# CTRL_MODULE_CORE register map
Vendor: Texas Instruments
Registers are 32-bit, access per field, reset 0x0 unless marked. A register's access mark holds for its fields unless they carry their own. Offsets are as the file gives them; [hi:lo] are bit positions; 'fields as' and 'values as' point back to an identical list.

## CTRL_MODULE_CORE (part 7 of 12)
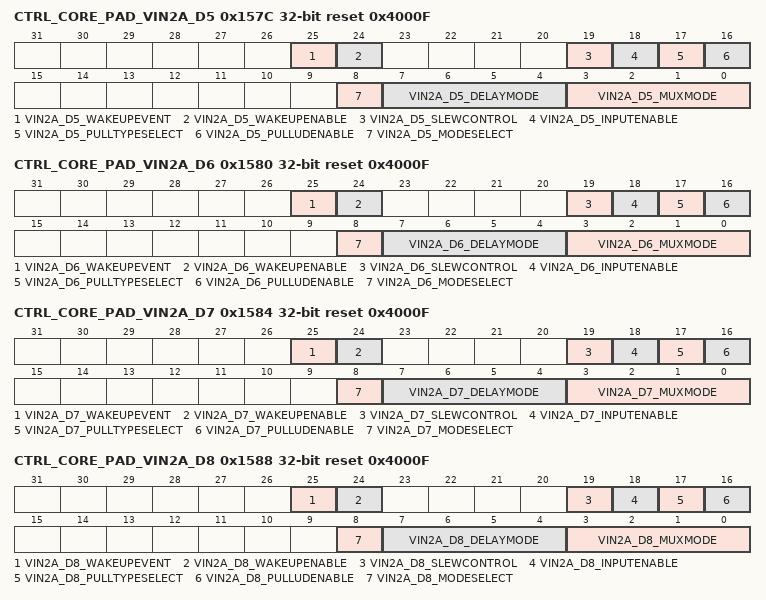
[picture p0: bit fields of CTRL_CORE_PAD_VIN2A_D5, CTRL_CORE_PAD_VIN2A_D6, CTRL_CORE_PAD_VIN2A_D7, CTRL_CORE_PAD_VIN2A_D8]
0x157C CTRL_CORE_PAD_VIN2A_D5 reset 0x4000F
  [25] VIN2A_D5_WAKEUPEVENT ro
    0=NOWAKEUP (No wakeup event detected); 1=WAKEUP (Wakeup event detected)
  [24] VIN2A_D5_WAKEUPENABLE rw
    0=DISABLE (Wakeup is disabled); 1=ENABLE (Wakeup is enabled)
  [19] VIN2A_D5_SLEWCONTROL rw
    0=FAST_SLEW (Fast slew is selected); 1=SLOW_SLEW (Slow slew is selected)
  [18] VIN2A_D5_INPUTENABLE rw
    0=DISABLE (Receive mode is disabled); 1=ENABLE (Receive mode is enabled)
  [17] VIN2A_D5_PULLTYPESELECT rw
    0=PULL_DOWN (Pull Down is selected); 1=PULL_UP (Pull Up is selected)
  [16] VIN2A_D5_PULLUDENABLE rw
    0=ENABLE (Enables weak Pull Up/Down); 1=DISABLE (Disables weak Pull Up/Down)
  [8] VIN2A_D5_MODESELECT rw — Selects between the Default IO Timing Mode and a Virtual or Manual IO Timing Mode. Refer to the device Data Manual for definition of the required settings for a given mode of operation. When this bit is 0b1, a Virtual IO Timing Mode can be selected via the DELAYMODE field of this register, as described in, Virtual IO Timing Modes. Manual IO Timing Modes are selected via the procedure described in , Manual IO Timing Modes.
    0=MUX_MODE (Default IO Timing Mode is used); 1=DELAY_MODE (A Virtual or Manual IO Timing Mode is used)
  [7:4] VIN2A_D5_DELAYMODE rw — This bit field selects the Virtual Timing Mode used when the MODESELECT bit is set to 0b1. See, Virtual IO Timing Modes for details.
  [3:0] VIN2A_D5_MUXMODE rw
    0=VIN2A_D5; 4=VOUT2_D18; 5=EMU15; 8=UART10_RTSN; 9=KBD_COL2; 10=EQEP2A_IN; 11=PR1_EDIO_SOF; 12=PR1_PRU1_GPI2; 13=PR1_PRU1_GPO2; 14=GPIO4_6; 15=DRIVER OFF
0x1580 CTRL_CORE_PAD_VIN2A_D6 reset 0x4000F
  [25] VIN2A_D6_WAKEUPEVENT ro
    values as CTRL_CORE_PAD_VIN2A_D5.VIN2A_D5_WAKEUPEVENT
  [24] VIN2A_D6_WAKEUPENABLE rw
    0=DISABLE (Wakeup is disabled); 1=ENABLE (Wakeup is enabled)
  [19] VIN2A_D6_SLEWCONTROL rw
    values as CTRL_CORE_PAD_VIN2A_D5.VIN2A_D5_SLEWCONTROL
  [18] VIN2A_D6_INPUTENABLE rw
    values as CTRL_CORE_PAD_VIN2A_D5.VIN2A_D5_INPUTENABLE
  [17] VIN2A_D6_PULLTYPESELECT rw
    values as CTRL_CORE_PAD_VIN2A_D5.VIN2A_D5_PULLTYPESELECT
  [16] VIN2A_D6_PULLUDENABLE rw
    values as CTRL_CORE_PAD_VIN2A_D5.VIN2A_D5_PULLUDENABLE
  [8] VIN2A_D6_MODESELECT rw — Selects between the Default IO Timing Mode and a Virtual or Manual IO Timing Mode. Refer to the device Data Manual for definition of the required settings for a given mode of operation. When this bit is 0b1, a Virtual IO Timing Mode can be selected via the DELAYMODE field of this register, as described in, Virtual IO Timing Modes. Manual IO Timing Modes are selected via the procedure described in , Manual IO Timing Modes.
    values as CTRL_CORE_PAD_VIN2A_D5.VIN2A_D5_MODESELECT
  [7:4] VIN2A_D6_DELAYMODE rw — This bit field selects the Virtual Timing Mode used when the MODESELECT bit is set to 0b1. See, Virtual IO Timing Modes for details.
  [3:0] VIN2A_D6_MUXMODE rw
    0=VIN2A_D6; 4=VOUT2_D17; 5=EMU16; 8=MII1_RXD1; 9=KBD_COL3; 10=EQEP2B_IN; 11=PR1_MII_MT1_CLK; 12=PR1_PRU1_GPI3; 13=PR1_PRU1_GPO3; 14=GPIO4_7; 15=DRIVER OFF
0x1584 CTRL_CORE_PAD_VIN2A_D7 reset 0x4000F
  [25] VIN2A_D7_WAKEUPEVENT ro
    values as CTRL_CORE_PAD_VIN2A_D5.VIN2A_D5_WAKEUPEVENT
  [24] VIN2A_D7_WAKEUPENABLE rw
    0=DISABLE (Wakeup is disabled); 1=ENABLE (Wakeup is enabled)
  [19] VIN2A_D7_SLEWCONTROL rw
    values as CTRL_CORE_PAD_VIN2A_D5.VIN2A_D5_SLEWCONTROL
  [18] VIN2A_D7_INPUTENABLE rw
    values as CTRL_CORE_PAD_VIN2A_D5.VIN2A_D5_INPUTENABLE
  [17] VIN2A_D7_PULLTYPESELECT rw
    values as CTRL_CORE_PAD_VIN2A_D5.VIN2A_D5_PULLTYPESELECT
  [16] VIN2A_D7_PULLUDENABLE rw
    values as CTRL_CORE_PAD_VIN2A_D5.VIN2A_D5_PULLUDENABLE
  [8] VIN2A_D7_MODESELECT rw — Selects between the Default IO Timing Mode and a Virtual or Manual IO Timing Mode. Refer to the device Data Manual for definition of the required settings for a given mode of operation. When this bit is 0b1, a Virtual IO Timing Mode can be selected via the DELAYMODE field of this register, as described in, Virtual IO Timing Modes. Manual IO Timing Modes are selected via the procedure described in , Manual IO Timing Modes.
    values as CTRL_CORE_PAD_VIN2A_D5.VIN2A_D5_MODESELECT
  [7:4] VIN2A_D7_DELAYMODE rw — This bit field selects the Virtual Timing Mode used when the MODESELECT bit is set to 0b1. See, Virtual IO Timing Modes for details.
  [3:0] VIN2A_D7_MUXMODE rw
    0=VIN2A_D7; 4=VOUT2_D16; 5=EMU17; 8=MII1_RXD2; 9=KBD_COL4; 10=EQEP2_INDEX; 11=PR1_MII1_TXEN; 12=PR1_PRU1_GPI4; 13=PR1_PRU1_GPO4; 14=GPIO4_8; 15=DRIVER OFF
0x1588 CTRL_CORE_PAD_VIN2A_D8 reset 0x4000F
  [25] VIN2A_D8_WAKEUPEVENT ro
    values as CTRL_CORE_PAD_VIN2A_D5.VIN2A_D5_WAKEUPEVENT
  [24] VIN2A_D8_WAKEUPENABLE rw
    0=DISABLE (Wakeup is disabled); 1=ENABLE (Wakeup is enabled)
  [19] VIN2A_D8_SLEWCONTROL rw
    values as CTRL_CORE_PAD_VIN2A_D5.VIN2A_D5_SLEWCONTROL
  [18] VIN2A_D8_INPUTENABLE rw
    values as CTRL_CORE_PAD_VIN2A_D5.VIN2A_D5_INPUTENABLE
  [17] VIN2A_D8_PULLTYPESELECT rw
    values as CTRL_CORE_PAD_VIN2A_D5.VIN2A_D5_PULLTYPESELECT
  [16] VIN2A_D8_PULLUDENABLE rw
    values as CTRL_CORE_PAD_VIN2A_D5.VIN2A_D5_PULLUDENABLE
  [8] VIN2A_D8_MODESELECT rw — Selects between the Default IO Timing Mode and a Virtual or Manual IO Timing Mode. Refer to the device Data Manual for definition of the required settings for a given mode of operation. When this bit is 0b1, a Virtual IO Timing Mode can be selected via the DELAYMODE field of this register, as described in, Virtual IO Timing Modes. Manual IO Timing Modes are selected via the procedure described in , Manual IO Timing Modes.
    values as CTRL_CORE_PAD_VIN2A_D5.VIN2A_D5_MODESELECT
  [7:4] VIN2A_D8_DELAYMODE rw — This bit field selects the Virtual Timing Mode used when the MODESELECT bit is set to 0b1. See, Virtual IO Timing Modes for details.
  [3:0] VIN2A_D8_MUXMODE rw
    0=VIN2A_D8; 4=VOUT2_D15; 5=EMU18; 8=MII1_RXD3; 9=KBD_COL5; 10=EQEP2_STROBE; 11=PR1_MII1_TXD3; 12=PR1_PRU1_GPI5; 13=PR1_PRU1_GPO5; 14=GPIO4_9; 15=DRIVER OFF
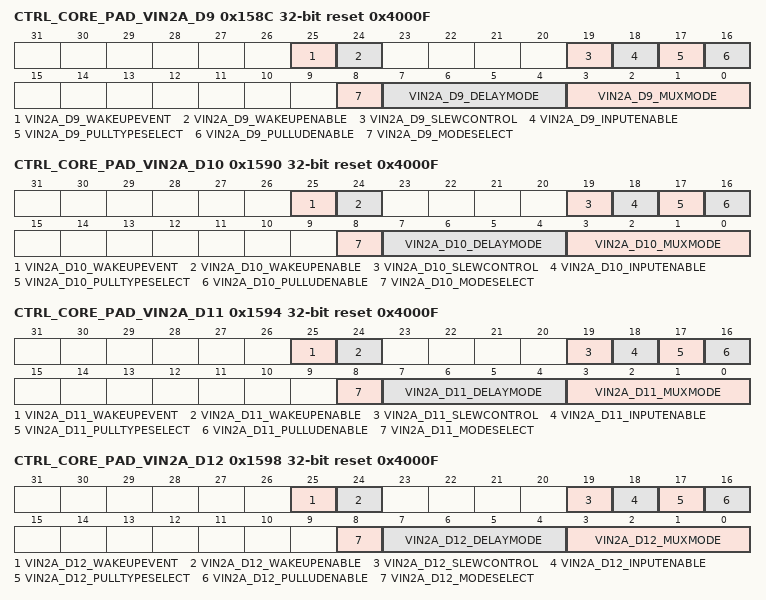
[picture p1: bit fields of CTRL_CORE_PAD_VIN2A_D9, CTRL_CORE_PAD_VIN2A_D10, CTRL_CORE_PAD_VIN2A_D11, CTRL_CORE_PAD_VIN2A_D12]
0x158C CTRL_CORE_PAD_VIN2A_D9 reset 0x4000F
  [25] VIN2A_D9_WAKEUPEVENT ro
    values as CTRL_CORE_PAD_VIN2A_D5.VIN2A_D5_WAKEUPEVENT
  [24] VIN2A_D9_WAKEUPENABLE rw
    0=DISABLE (Wakeup is disabled); 1=ENABLE (Wakeup is enabled)
  [19] VIN2A_D9_SLEWCONTROL rw
    values as CTRL_CORE_PAD_VIN2A_D5.VIN2A_D5_SLEWCONTROL
  [18] VIN2A_D9_INPUTENABLE rw
    values as CTRL_CORE_PAD_VIN2A_D5.VIN2A_D5_INPUTENABLE
  [17] VIN2A_D9_PULLTYPESELECT rw
    values as CTRL_CORE_PAD_VIN2A_D5.VIN2A_D5_PULLTYPESELECT
  [16] VIN2A_D9_PULLUDENABLE rw
    values as CTRL_CORE_PAD_VIN2A_D5.VIN2A_D5_PULLUDENABLE
  [8] VIN2A_D9_MODESELECT rw — Selects between the Default IO Timing Mode and a Virtual or Manual IO Timing Mode. Refer to the device Data Manual for definition of the required settings for a given mode of operation. When this bit is 0b1, a Virtual IO Timing Mode can be selected via the DELAYMODE field of this register, as described in, Virtual IO Timing Modes. Manual IO Timing Modes are selected via the procedure described in , Manual IO Timing Modes.
    values as CTRL_CORE_PAD_VIN2A_D5.VIN2A_D5_MODESELECT
  [7:4] VIN2A_D9_DELAYMODE rw — This bit field selects the Virtual Timing Mode used when the MODESELECT bit is set to 0b1. See, Virtual IO Timing Modes for details.
  [3:0] VIN2A_D9_MUXMODE rw
    0=VIN2A_D9; 4=VOUT2_D14; 5=EMU19; 8=MII1_RXD0; 9=KBD_COL6; 10=EHRPWM2A; 11=PR1_MII1_TXD2; 12=PR1_PRU1_GPI6; 13=PR1_PRU1_GPO6; 14=GPIO4_10; 15=DRIVER OFF
0x1590 CTRL_CORE_PAD_VIN2A_D10 reset 0x4000F
  [25] VIN2A_D10_WAKEUPEVENT ro
    values as CTRL_CORE_PAD_VIN2A_D5.VIN2A_D5_WAKEUPEVENT
  [24] VIN2A_D10_WAKEUPENABLE rw
    0=DISABLE (Wakeup is disabled); 1=ENABLE (Wakeup is enabled)
  [19] VIN2A_D10_SLEWCONTROL rw
    values as CTRL_CORE_PAD_VIN2A_D5.VIN2A_D5_SLEWCONTROL
  [18] VIN2A_D10_INPUTENABLE rw
    values as CTRL_CORE_PAD_VIN2A_D5.VIN2A_D5_INPUTENABLE
  [17] VIN2A_D10_PULLTYPESELECT rw
    values as CTRL_CORE_PAD_VIN2A_D5.VIN2A_D5_PULLTYPESELECT
  [16] VIN2A_D10_PULLUDENABLE rw
    values as CTRL_CORE_PAD_VIN2A_D5.VIN2A_D5_PULLUDENABLE
  [8] VIN2A_D10_MODESELECT rw — Selects between the Default IO Timing Mode and a Virtual or Manual IO Timing Mode. Refer to the device Data Manual for definition of the required settings for a given mode of operation. When this bit is 0b1, a Virtual IO Timing Mode can be selected via the DELAYMODE field of this register, as described in, Virtual IO Timing Modes. Manual IO Timing Modes are selected via the procedure described in , Manual IO Timing Modes.
    values as CTRL_CORE_PAD_VIN2A_D5.VIN2A_D5_MODESELECT
  [7:4] VIN2A_D10_DELAYMODE rw — This bit field selects the Virtual Timing Mode used when the MODESELECT bit is set to 0b1. See, Virtual IO Timing Modes for details.
  [3:0] VIN2A_D10_MUXMODE rw
    0=VIN2A_D10; 3=MDIO_MCLK; 4=VOUT2_D13; 9=KBD_COL7; 10=EHRPWM2B; 11=PR1_MDIO_MDCLK; 12=PR1_PRU1_GPI7; 13=PR1_PRU1_GPO7; 14=GPIO4_11; 15=DRIVER OFF
0x1594 CTRL_CORE_PAD_VIN2A_D11 reset 0x4000F
  [25] VIN2A_D11_WAKEUPEVENT ro
    values as CTRL_CORE_PAD_VIN2A_D5.VIN2A_D5_WAKEUPEVENT
  [24] VIN2A_D11_WAKEUPENABLE rw
    0=DISABLE (Wakeup is disabled); 1=ENABLE (Wakeup is enabled)
  [19] VIN2A_D11_SLEWCONTROL rw
    values as CTRL_CORE_PAD_VIN2A_D5.VIN2A_D5_SLEWCONTROL
  [18] VIN2A_D11_INPUTENABLE rw
    values as CTRL_CORE_PAD_VIN2A_D5.VIN2A_D5_INPUTENABLE
  [17] VIN2A_D11_PULLTYPESELECT rw
    values as CTRL_CORE_PAD_VIN2A_D5.VIN2A_D5_PULLTYPESELECT
  [16] VIN2A_D11_PULLUDENABLE rw
    values as CTRL_CORE_PAD_VIN2A_D5.VIN2A_D5_PULLUDENABLE
  [8] VIN2A_D11_MODESELECT rw — Selects between the Default IO Timing Mode and a Virtual or Manual IO Timing Mode. Refer to the device Data Manual for definition of the required settings for a given mode of operation. When this bit is 0b1, a Virtual IO Timing Mode can be selected via the DELAYMODE field of this register, as described in, Virtual IO Timing Modes. Manual IO Timing Modes are selected via the procedure described in , Manual IO Timing Modes.
    values as CTRL_CORE_PAD_VIN2A_D5.VIN2A_D5_MODESELECT
  [7:4] VIN2A_D11_DELAYMODE rw — This bit field selects the Virtual Timing Mode used when the MODESELECT bit is set to 0b1. See, Virtual IO Timing Modes for details.
  [3:0] VIN2A_D11_MUXMODE rw
    0=VIN2A_D11; 3=MDIO_D; 4=VOUT2_D12; 9=KBD_ROW7; 10=EHRPWM2_TRIPZONE_INPUT; 11=PR1_MDIO_DATA; 12=PR1_PRU1_GPI8; 13=PR1_PRU1_GPO8; 14=GPIO4_12; 15=DRIVER OFF
0x1598 CTRL_CORE_PAD_VIN2A_D12 reset 0x4000F
  [25] VIN2A_D12_WAKEUPEVENT ro
    values as CTRL_CORE_PAD_VIN2A_D5.VIN2A_D5_WAKEUPEVENT
  [24] VIN2A_D12_WAKEUPENABLE rw
    0=DISABLE (Wakeup is disabled); 1=ENABLE (Wakeup is enabled)
  [19] VIN2A_D12_SLEWCONTROL rw
    values as CTRL_CORE_PAD_VIN2A_D5.VIN2A_D5_SLEWCONTROL
  [18] VIN2A_D12_INPUTENABLE rw
    values as CTRL_CORE_PAD_VIN2A_D5.VIN2A_D5_INPUTENABLE
  [17] VIN2A_D12_PULLTYPESELECT rw
    values as CTRL_CORE_PAD_VIN2A_D5.VIN2A_D5_PULLTYPESELECT
  [16] VIN2A_D12_PULLUDENABLE rw
    values as CTRL_CORE_PAD_VIN2A_D5.VIN2A_D5_PULLUDENABLE
  [8] VIN2A_D12_MODESELECT rw — Selects between the Default IO Timing Mode and a Virtual or Manual IO Timing Mode. Refer to the device Data Manual for definition of the required settings for a given mode of operation. When this bit is 0b1, a Virtual IO Timing Mode can be selected via the DELAYMODE field of this register, as described in, Virtual IO Timing Modes. Manual IO Timing Modes are selected via the procedure described in , Manual IO Timing Modes.
    values as CTRL_CORE_PAD_VIN2A_D5.VIN2A_D5_MODESELECT
  [7:4] VIN2A_D12_DELAYMODE rw — This bit field selects the Virtual Timing Mode used when the MODESELECT bit is set to 0b1. See, Virtual IO Timing Modes for details.
  [3:0] VIN2A_D12_MUXMODE rw
    0=VIN2A_D12; 3=RGMII1_TXC; 4=VOUT2_D11; 8=MII1_RXCLK; 9=KBD_COL8; 10=ECAP2_IN_PWM2_OUT; 11=PR1_MII1_TXD1; 12=PR1_PRU1_GPI9; 13=PR1_PRU1_GPO9; 14=GPIO4_13; 15=DRIVER OFF
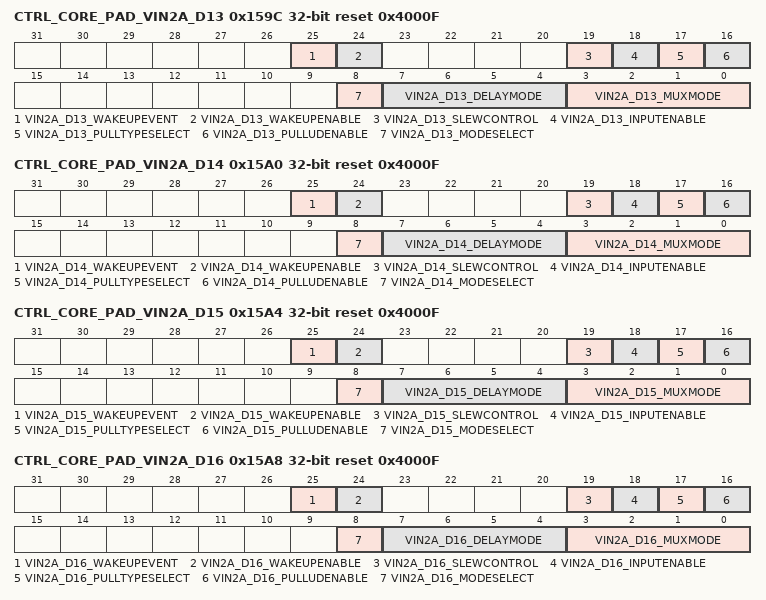
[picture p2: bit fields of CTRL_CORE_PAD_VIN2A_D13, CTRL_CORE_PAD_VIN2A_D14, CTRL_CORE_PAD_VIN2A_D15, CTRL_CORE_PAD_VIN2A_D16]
0x159C CTRL_CORE_PAD_VIN2A_D13 reset 0x4000F
  [25] VIN2A_D13_WAKEUPEVENT ro
    values as CTRL_CORE_PAD_VIN2A_D5.VIN2A_D5_WAKEUPEVENT
  [24] VIN2A_D13_WAKEUPENABLE rw
    0=DISABLE (Wakeup is disabled); 1=ENABLE (Wakeup is enabled)
  [19] VIN2A_D13_SLEWCONTROL rw
    values as CTRL_CORE_PAD_VIN2A_D5.VIN2A_D5_SLEWCONTROL
  [18] VIN2A_D13_INPUTENABLE rw
    values as CTRL_CORE_PAD_VIN2A_D5.VIN2A_D5_INPUTENABLE
  [17] VIN2A_D13_PULLTYPESELECT rw
    values as CTRL_CORE_PAD_VIN2A_D5.VIN2A_D5_PULLTYPESELECT
  [16] VIN2A_D13_PULLUDENABLE rw
    values as CTRL_CORE_PAD_VIN2A_D5.VIN2A_D5_PULLUDENABLE
  [8] VIN2A_D13_MODESELECT rw — Selects between the Default IO Timing Mode and a Virtual or Manual IO Timing Mode. Refer to the device Data Manual for definition of the required settings for a given mode of operation. When this bit is 0b1, a Virtual IO Timing Mode can be selected via the DELAYMODE field of this register, as described in, Virtual IO Timing Modes. Manual IO Timing Modes are selected via the procedure described in , Manual IO Timing Modes.
    values as CTRL_CORE_PAD_VIN2A_D5.VIN2A_D5_MODESELECT
  [7:4] VIN2A_D13_DELAYMODE rw — This bit field selects the Virtual Timing Mode used when the MODESELECT bit is set to 0b1. See, Virtual IO Timing Modes for details.
  [3:0] VIN2A_D13_MUXMODE rw
    0=VIN2A_D13; 3=RGMII1_TXCTL; 4=VOUT2_D10; 8=MII1_RXDV; 9=KBD_ROW8; 10=EQEP3A_IN; 11=PR1_MII1_TXD0; 12=PR1_PRU1_GPI10; 13=PR1_PRU1_GPO10; 14=GPIO4_14; 15=DRIVER OFF
0x15A0 CTRL_CORE_PAD_VIN2A_D14 reset 0x4000F
  [25] VIN2A_D14_WAKEUPEVENT ro
    values as CTRL_CORE_PAD_VIN2A_D5.VIN2A_D5_WAKEUPEVENT
  [24] VIN2A_D14_WAKEUPENABLE rw
    0=DISABLE (Wakeup is disabled); 1=ENABLE (Wakeup is enabled)
  [19] VIN2A_D14_SLEWCONTROL rw
    values as CTRL_CORE_PAD_VIN2A_D5.VIN2A_D5_SLEWCONTROL
  [18] VIN2A_D14_INPUTENABLE rw
    values as CTRL_CORE_PAD_VIN2A_D5.VIN2A_D5_INPUTENABLE
  [17] VIN2A_D14_PULLTYPESELECT rw
    values as CTRL_CORE_PAD_VIN2A_D5.VIN2A_D5_PULLTYPESELECT
  [16] VIN2A_D14_PULLUDENABLE rw
    values as CTRL_CORE_PAD_VIN2A_D5.VIN2A_D5_PULLUDENABLE
  [8] VIN2A_D14_MODESELECT rw — Selects between the Default IO Timing Mode and a Virtual or Manual IO Timing Mode. Refer to the device Data Manual for definition of the required settings for a given mode of operation. When this bit is 0b1, a Virtual IO Timing Mode can be selected via the DELAYMODE field of this register, as described in, Virtual IO Timing Modes. Manual IO Timing Modes are selected via the procedure described in , Manual IO Timing Modes.
    values as CTRL_CORE_PAD_VIN2A_D5.VIN2A_D5_MODESELECT
  [7:4] VIN2A_D14_DELAYMODE rw — This bit field selects the Virtual Timing Mode used when the MODESELECT bit is set to 0b1. See, Virtual IO Timing Modes for details.
  [3:0] VIN2A_D14_MUXMODE rw
    0=VIN2A_D14; 3=RGMII1_TXD3; 4=VOUT2_D9; 8=MII1_TXCLK; 10=EQEP3B_IN; 11=PR1_MII_MR1_CLK; 12=PR1_PRU1_GPI11; 13=PR1_PRU1_GPO11; 14=GPIO4_15; 15=DRIVER OFF
0x15A4 CTRL_CORE_PAD_VIN2A_D15 reset 0x4000F
  [25] VIN2A_D15_WAKEUPEVENT ro
    values as CTRL_CORE_PAD_VIN2A_D5.VIN2A_D5_WAKEUPEVENT
  [24] VIN2A_D15_WAKEUPENABLE rw
    0=DISABLE (Wakeup is disabled); 1=ENABLE (Wakeup is enabled)
  [19] VIN2A_D15_SLEWCONTROL rw
    values as CTRL_CORE_PAD_VIN2A_D5.VIN2A_D5_SLEWCONTROL
  [18] VIN2A_D15_INPUTENABLE rw
    values as CTRL_CORE_PAD_VIN2A_D5.VIN2A_D5_INPUTENABLE
  [17] VIN2A_D15_PULLTYPESELECT rw
    values as CTRL_CORE_PAD_VIN2A_D5.VIN2A_D5_PULLTYPESELECT
  [16] VIN2A_D15_PULLUDENABLE rw
    values as CTRL_CORE_PAD_VIN2A_D5.VIN2A_D5_PULLUDENABLE
  [8] VIN2A_D15_MODESELECT rw — Selects between the Default IO Timing Mode and a Virtual or Manual IO Timing Mode. Refer to the device Data Manual for definition of the required settings for a given mode of operation. When this bit is 0b1, a Virtual IO Timing Mode can be selected via the DELAYMODE field of this register, as described in, Virtual IO Timing Modes. Manual IO Timing Modes are selected via the procedure described in , Manual IO Timing Modes.
    values as CTRL_CORE_PAD_VIN2A_D5.VIN2A_D5_MODESELECT
  [7:4] VIN2A_D15_DELAYMODE rw — This bit field selects the Virtual Timing Mode used when the MODESELECT bit is set to 0b1. See, Virtual IO Timing Modes for details.
  [3:0] VIN2A_D15_MUXMODE rw
    0=VIN2A_D15; 3=RGMII1_TXD2; 4=VOUT2_D8; 8=MII1_TXD0; 10=EQEP3_INDEX; 11=PR1_MII1_RXDV; 12=PR1_PRU1_GPI12; 13=PR1_PRU1_GPO12; 14=GPIO4_16; 15=DRIVER OFF
0x15A8 CTRL_CORE_PAD_VIN2A_D16 reset 0x4000F
  [25] VIN2A_D16_WAKEUPEVENT ro
    values as CTRL_CORE_PAD_VIN2A_D5.VIN2A_D5_WAKEUPEVENT
  [24] VIN2A_D16_WAKEUPENABLE rw
    0=DISABLE (Wakeup is disabled); 1=ENABLE (Wakeup is enabled)
  [19] VIN2A_D16_SLEWCONTROL rw
    values as CTRL_CORE_PAD_VIN2A_D5.VIN2A_D5_SLEWCONTROL
  [18] VIN2A_D16_INPUTENABLE rw
    values as CTRL_CORE_PAD_VIN2A_D5.VIN2A_D5_INPUTENABLE
  [17] VIN2A_D16_PULLTYPESELECT rw
    values as CTRL_CORE_PAD_VIN2A_D5.VIN2A_D5_PULLTYPESELECT
  [16] VIN2A_D16_PULLUDENABLE rw
    values as CTRL_CORE_PAD_VIN2A_D5.VIN2A_D5_PULLUDENABLE
  [8] VIN2A_D16_MODESELECT rw — Selects between the Default IO Timing Mode and a Virtual or Manual IO Timing Mode. Refer to the device Data Manual for definition of the required settings for a given mode of operation. When this bit is 0b1, a Virtual IO Timing Mode can be selected via the DELAYMODE field of this register, as described in, Virtual IO Timing Modes. Manual IO Timing Modes are selected via the procedure described in , Manual IO Timing Modes.
    values as CTRL_CORE_PAD_VIN2A_D5.VIN2A_D5_MODESELECT
  [7:4] VIN2A_D16_DELAYMODE rw — This bit field selects the Virtual Timing Mode used when the MODESELECT bit is set to 0b1. See, Virtual IO Timing Modes for details.
  [3:0] VIN2A_D16_MUXMODE rw
    0=VIN2A_D16; 2=VIN2B_D7; 3=RGMII1_TXD1; 4=VOUT2_D7; 6=VIN3A_D8; 8=MII1_TXD1; 10=EQEP3_STROBE; 11=PR1_MII1_RXD3; 12=PR1_PRU1_GPI13; 13=PR1_PRU1_GPO13; 14=GPIO4_24; 15=DRIVER OFF
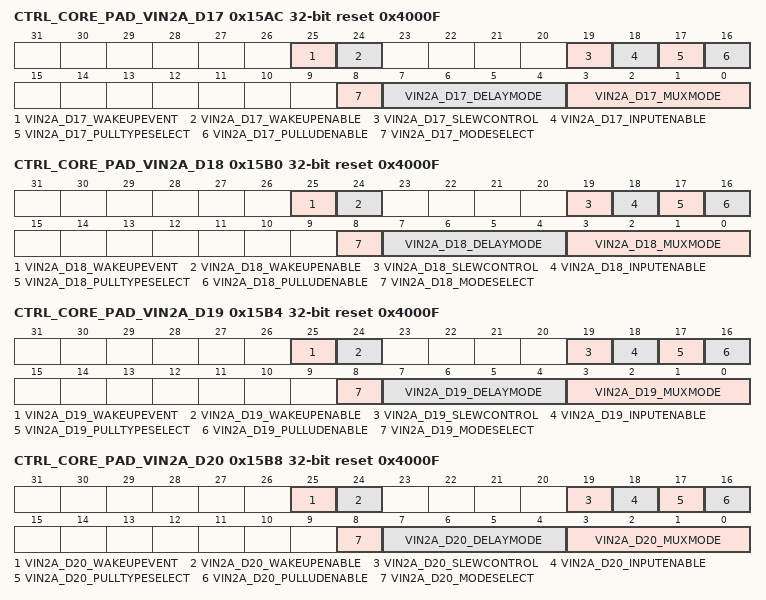
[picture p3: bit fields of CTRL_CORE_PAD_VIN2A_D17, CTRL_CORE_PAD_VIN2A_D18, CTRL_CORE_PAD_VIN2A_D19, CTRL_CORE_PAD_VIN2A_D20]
0x15AC CTRL_CORE_PAD_VIN2A_D17 reset 0x4000F
  [25] VIN2A_D17_WAKEUPEVENT ro
    values as CTRL_CORE_PAD_VIN2A_D5.VIN2A_D5_WAKEUPEVENT
  [24] VIN2A_D17_WAKEUPENABLE rw
    0=DISABLE (Wakeup is disabled); 1=ENABLE (Wakeup is enabled)
  [19] VIN2A_D17_SLEWCONTROL rw
    values as CTRL_CORE_PAD_VIN2A_D5.VIN2A_D5_SLEWCONTROL
  [18] VIN2A_D17_INPUTENABLE rw
    values as CTRL_CORE_PAD_VIN2A_D5.VIN2A_D5_INPUTENABLE
  [17] VIN2A_D17_PULLTYPESELECT rw
    values as CTRL_CORE_PAD_VIN2A_D5.VIN2A_D5_PULLTYPESELECT
  [16] VIN2A_D17_PULLUDENABLE rw
    values as CTRL_CORE_PAD_VIN2A_D5.VIN2A_D5_PULLUDENABLE
  [8] VIN2A_D17_MODESELECT rw — Selects between the Default IO Timing Mode and a Virtual or Manual IO Timing Mode. Refer to the device Data Manual for definition of the required settings for a given mode of operation. When this bit is 0b1, a Virtual IO Timing Mode can be selected via the DELAYMODE field of this register, as described in, Virtual IO Timing Modes. Manual IO Timing Modes are selected via the procedure described in , Manual IO Timing Modes.
    values as CTRL_CORE_PAD_VIN2A_D5.VIN2A_D5_MODESELECT
  [7:4] VIN2A_D17_DELAYMODE rw — This bit field selects the Virtual Timing Mode used when the MODESELECT bit is set to 0b1. See, Virtual IO Timing Modes for details.
  [3:0] VIN2A_D17_MUXMODE rw
    0=VIN2A_D17; 2=VIN2B_D6; 3=RGMII1_TXD0; 4=VOUT2_D6; 6=VIN3A_D9; 8=MII1_TXD2; 10=EHRPWM3A; 11=PR1_MII1_RXD2; 12=PR1_PRU1_GPI14; 13=PR1_PRU1_GPO14; 14=GPIO4_25; 15=DRIVER OFF
0x15B0 CTRL_CORE_PAD_VIN2A_D18 reset 0x4000F
  [25] VIN2A_D18_WAKEUPEVENT ro
    values as CTRL_CORE_PAD_VIN2A_D5.VIN2A_D5_WAKEUPEVENT
  [24] VIN2A_D18_WAKEUPENABLE rw
    0=DISABLE (Wakeup is disabled); 1=ENABLE (Wakeup is enabled)
  [19] VIN2A_D18_SLEWCONTROL rw
    values as CTRL_CORE_PAD_VIN2A_D5.VIN2A_D5_SLEWCONTROL
  [18] VIN2A_D18_INPUTENABLE rw
    values as CTRL_CORE_PAD_VIN2A_D5.VIN2A_D5_INPUTENABLE
  [17] VIN2A_D18_PULLTYPESELECT rw
    values as CTRL_CORE_PAD_VIN2A_D5.VIN2A_D5_PULLTYPESELECT
  [16] VIN2A_D18_PULLUDENABLE rw
    values as CTRL_CORE_PAD_VIN2A_D5.VIN2A_D5_PULLUDENABLE
  [8] VIN2A_D18_MODESELECT rw — Selects between the Default IO Timing Mode and a Virtual or Manual IO Timing Mode. Refer to the device Data Manual for definition of the required settings for a given mode of operation. When this bit is 0b1, a Virtual IO Timing Mode can be selected via the DELAYMODE field of this register, as described in, Virtual IO Timing Modes. Manual IO Timing Modes are selected via the procedure described in , Manual IO Timing Modes.
    values as CTRL_CORE_PAD_VIN2A_D5.VIN2A_D5_MODESELECT
  [7:4] VIN2A_D18_DELAYMODE rw — This bit field selects the Virtual Timing Mode used when the MODESELECT bit is set to 0b1. See, Virtual IO Timing Modes for details.
  [3:0] VIN2A_D18_MUXMODE rw
    0=VIN2A_D18; 2=VIN2B_D5; 3=RGMII1_RXC; 4=VOUT2_D5; 6=VIN3A_D10; 8=MII1_TXD3; 10=EHRPWM3B; 11=PR1_MII1_RXD1; 12=PR1_PRU1_GPI15; 13=PR1_PRU1_GPO15; 14=GPIO4_26; 15=DRIVER OFF
0x15B4 CTRL_CORE_PAD_VIN2A_D19 reset 0x4000F
  [25] VIN2A_D19_WAKEUPEVENT ro
    values as CTRL_CORE_PAD_VIN2A_D5.VIN2A_D5_WAKEUPEVENT
  [24] VIN2A_D19_WAKEUPENABLE rw
    0=DISABLE (Wakeup is disabled); 1=ENABLE (Wakeup is enabled)
  [19] VIN2A_D19_SLEWCONTROL rw
    values as CTRL_CORE_PAD_VIN2A_D5.VIN2A_D5_SLEWCONTROL
  [18] VIN2A_D19_INPUTENABLE rw
    values as CTRL_CORE_PAD_VIN2A_D5.VIN2A_D5_INPUTENABLE
  [17] VIN2A_D19_PULLTYPESELECT rw
    values as CTRL_CORE_PAD_VIN2A_D5.VIN2A_D5_PULLTYPESELECT
  [16] VIN2A_D19_PULLUDENABLE rw
    values as CTRL_CORE_PAD_VIN2A_D5.VIN2A_D5_PULLUDENABLE
  [8] VIN2A_D19_MODESELECT rw — Selects between the Default IO Timing Mode and a Virtual or Manual IO Timing Mode. Refer to the device Data Manual for definition of the required settings for a given mode of operation. When this bit is 0b1, a Virtual IO Timing Mode can be selected via the DELAYMODE field of this register, as described in, Virtual IO Timing Modes. Manual IO Timing Modes are selected via the procedure described in , Manual IO Timing Modes.
    values as CTRL_CORE_PAD_VIN2A_D5.VIN2A_D5_MODESELECT
  [7:4] VIN2A_D19_DELAYMODE rw — This bit field selects the Virtual Timing Mode used when the MODESELECT bit is set to 0b1. See, Virtual IO Timing Modes for details.
  [3:0] VIN2A_D19_MUXMODE rw
    0=VIN2A_D19; 2=VIN2B_D4; 3=RGMII1_RXCTL; 4=VOUT2_D4; 6=VIN3A_D11; 8=MII1_TXER; 10=EHRPWM3_TRIPZONE_INPUT; 11=PR1_MII1_RXD0; 12=PR1_PRU1_GPI16; 13=PR1_PRU1_GPO16; 14=GPIO4_27; 15=DRIVER OFF
0x15B8 CTRL_CORE_PAD_VIN2A_D20 reset 0x4000F
  [25] VIN2A_D20_WAKEUPEVENT ro
    values as CTRL_CORE_PAD_VIN2A_D5.VIN2A_D5_WAKEUPEVENT
  [24] VIN2A_D20_WAKEUPENABLE rw
    0=DISABLE (Wakeup is disabled); 1=ENABLE (Wakeup is enabled)
  [19] VIN2A_D20_SLEWCONTROL rw
    values as CTRL_CORE_PAD_VIN2A_D5.VIN2A_D5_SLEWCONTROL
  [18] VIN2A_D20_INPUTENABLE rw
    values as CTRL_CORE_PAD_VIN2A_D5.VIN2A_D5_INPUTENABLE
  [17] VIN2A_D20_PULLTYPESELECT rw
    values as CTRL_CORE_PAD_VIN2A_D5.VIN2A_D5_PULLTYPESELECT
  [16] VIN2A_D20_PULLUDENABLE rw
    values as CTRL_CORE_PAD_VIN2A_D5.VIN2A_D5_PULLUDENABLE
  [8] VIN2A_D20_MODESELECT rw — Selects between the Default IO Timing Mode and a Virtual or Manual IO Timing Mode. Refer to the device Data Manual for definition of the required settings for a given mode of operation. When this bit is 0b1, a Virtual IO Timing Mode can be selected via the DELAYMODE field of this register, as described in, Virtual IO Timing Modes. Manual IO Timing Modes are selected via the procedure described in , Manual IO Timing Modes.
    values as CTRL_CORE_PAD_VIN2A_D5.VIN2A_D5_MODESELECT
  [7:4] VIN2A_D20_DELAYMODE rw — This bit field selects the Virtual Timing Mode used when the MODESELECT bit is set to 0b1. See, Virtual IO Timing Modes for details.
  [3:0] VIN2A_D20_MUXMODE rw
    0=VIN2A_D20; 2=VIN2B_D3; 3=RGMII1_RXD3; 4=VOUT2_D3; 5=VIN3A_DE0; 6=VIN3A_D12; 8=MII1_RXER; 10=ECAP3_IN_PWM3_OUT; 11=PR1_MII1_RXER; 12=PR1_PRU1_GPI17; 13=PR1_PRU1_GPO17; 14=GPIO4_28; 15=DRIVER OFF
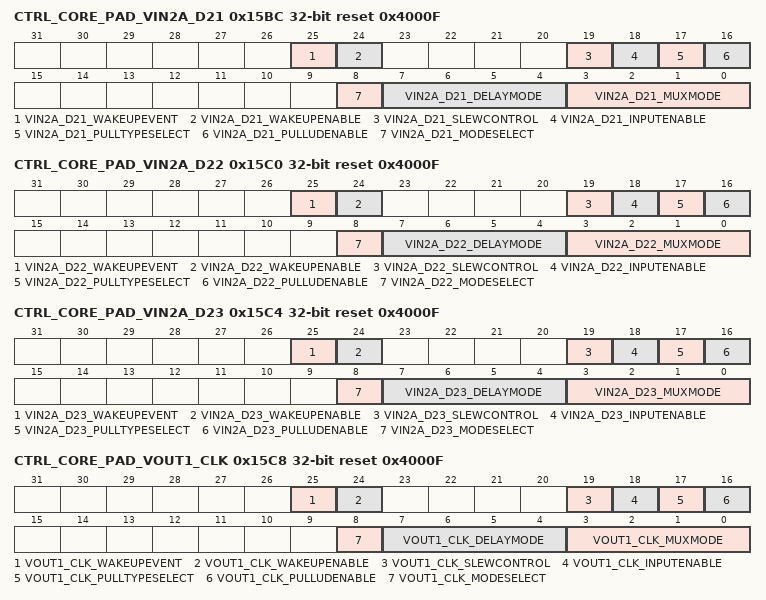
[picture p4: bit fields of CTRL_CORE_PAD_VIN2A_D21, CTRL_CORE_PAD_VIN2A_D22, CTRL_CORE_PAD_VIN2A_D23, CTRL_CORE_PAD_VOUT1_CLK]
0x15BC CTRL_CORE_PAD_VIN2A_D21 reset 0x4000F
  [25] VIN2A_D21_WAKEUPEVENT ro
    values as CTRL_CORE_PAD_VIN2A_D5.VIN2A_D5_WAKEUPEVENT
  [24] VIN2A_D21_WAKEUPENABLE rw
    0=DISABLE (Wakeup is disabled); 1=ENABLE (Wakeup is enabled)
  [19] VIN2A_D21_SLEWCONTROL rw
    values as CTRL_CORE_PAD_VIN2A_D5.VIN2A_D5_SLEWCONTROL
  [18] VIN2A_D21_INPUTENABLE rw
    values as CTRL_CORE_PAD_VIN2A_D5.VIN2A_D5_INPUTENABLE
  [17] VIN2A_D21_PULLTYPESELECT rw
    values as CTRL_CORE_PAD_VIN2A_D5.VIN2A_D5_PULLTYPESELECT
  [16] VIN2A_D21_PULLUDENABLE rw
    values as CTRL_CORE_PAD_VIN2A_D5.VIN2A_D5_PULLUDENABLE
  [8] VIN2A_D21_MODESELECT rw — Selects between the Default IO Timing Mode and a Virtual or Manual IO Timing Mode. Refer to the device Data Manual for definition of the required settings for a given mode of operation. When this bit is 0b1, a Virtual IO Timing Mode can be selected via the DELAYMODE field of this register, as described in, Virtual IO Timing Modes. Manual IO Timing Modes are selected via the procedure described in , Manual IO Timing Modes.
    values as CTRL_CORE_PAD_VIN2A_D5.VIN2A_D5_MODESELECT
  [7:4] VIN2A_D21_DELAYMODE rw — This bit field selects the Virtual Timing Mode used when the MODESELECT bit is set to 0b1. See, Virtual IO Timing Modes for details.
  [3:0] VIN2A_D21_MUXMODE rw
    0=VIN2A_D21; 2=VIN2B_D2; 3=RGMII1_RXD2; 4=VOUT2_D2; 5=VIN3A_FLD0; 6=VIN3A_D13; 8=MII1_COL; 11=PR1_MII1_RXLINK; 12=PR1_PRU1_GPI18; 13=PR1_PRU1_GPO18; 14=GPIO4_29; 15=DRIVER OFF
0x15C0 CTRL_CORE_PAD_VIN2A_D22 reset 0x4000F
  [25] VIN2A_D22_WAKEUPEVENT ro
    values as CTRL_CORE_PAD_VIN2A_D5.VIN2A_D5_WAKEUPEVENT
  [24] VIN2A_D22_WAKEUPENABLE rw
    0=DISABLE (Wakeup is disabled); 1=ENABLE (Wakeup is enabled)
  [19] VIN2A_D22_SLEWCONTROL rw
    values as CTRL_CORE_PAD_VIN2A_D5.VIN2A_D5_SLEWCONTROL
  [18] VIN2A_D22_INPUTENABLE rw
    values as CTRL_CORE_PAD_VIN2A_D5.VIN2A_D5_INPUTENABLE
  [17] VIN2A_D22_PULLTYPESELECT rw
    values as CTRL_CORE_PAD_VIN2A_D5.VIN2A_D5_PULLTYPESELECT
  [16] VIN2A_D22_PULLUDENABLE rw
    values as CTRL_CORE_PAD_VIN2A_D5.VIN2A_D5_PULLUDENABLE
  [8] VIN2A_D22_MODESELECT rw — Selects between the Default IO Timing Mode and a Virtual or Manual IO Timing Mode. Refer to the device Data Manual for definition of the required settings for a given mode of operation. When this bit is 0b1, a Virtual IO Timing Mode can be selected via the DELAYMODE field of this register, as described in, Virtual IO Timing Modes. Manual IO Timing Modes are selected via the procedure described in , Manual IO Timing Modes.
    values as CTRL_CORE_PAD_VIN2A_D5.VIN2A_D5_MODESELECT
  [7:4] VIN2A_D22_DELAYMODE rw — This bit field selects the Virtual Timing Mode used when the MODESELECT bit is set to 0b1. See, Virtual IO Timing Modes for details.
  [3:0] VIN2A_D22_MUXMODE rw
    0=VIN2A_D22; 2=VIN2B_D1; 3=RGMII1_RXD1; 4=VOUT2_D1; 5=VIN3A_HSYNC0; 6=VIN3A_D14; 8=MII1_CRS; 11=PR1_MII1_COL; 12=PR1_PRU1_GPI19; 13=PR1_PRU1_GPO19; 14=GPIO4_30; 15=DRIVER OFF
0x15C4 CTRL_CORE_PAD_VIN2A_D23 reset 0x4000F
  [25] VIN2A_D23_WAKEUPEVENT ro
    values as CTRL_CORE_PAD_VIN2A_D5.VIN2A_D5_WAKEUPEVENT
  [24] VIN2A_D23_WAKEUPENABLE rw
    0=DISABLE (Wakeup is disabled); 1=ENABLE (Wakeup is enabled)
  [19] VIN2A_D23_SLEWCONTROL rw
    values as CTRL_CORE_PAD_VIN2A_D5.VIN2A_D5_SLEWCONTROL
  [18] VIN2A_D23_INPUTENABLE rw
    values as CTRL_CORE_PAD_VIN2A_D5.VIN2A_D5_INPUTENABLE
  [17] VIN2A_D23_PULLTYPESELECT rw
    values as CTRL_CORE_PAD_VIN2A_D5.VIN2A_D5_PULLTYPESELECT
  [16] VIN2A_D23_PULLUDENABLE rw
    values as CTRL_CORE_PAD_VIN2A_D5.VIN2A_D5_PULLUDENABLE
  [8] VIN2A_D23_MODESELECT rw — Selects between the Default IO Timing Mode and a Virtual or Manual IO Timing Mode. Refer to the device Data Manual for definition of the required settings for a given mode of operation. When this bit is 0b1, a Virtual IO Timing Mode can be selected via the DELAYMODE field of this register, as described in, Virtual IO Timing Modes. Manual IO Timing Modes are selected via the procedure described in , Manual IO Timing Modes.
    values as CTRL_CORE_PAD_VIN2A_D5.VIN2A_D5_MODESELECT
  [7:4] VIN2A_D23_DELAYMODE rw — This bit field selects the Virtual Timing Mode used when the MODESELECT bit is set to 0b1. See, Virtual IO Timing Modes for details.
  [3:0] VIN2A_D23_MUXMODE rw
    0=VIN2A_D23; 2=VIN2B_D0; 3=RGMII1_RXD0; 4=VOUT2_D0; 5=VIN3A_VSYNC0; 6=VIN3A_D15; 8=MII1_TXEN; 11=PR1_MII1_CRS; 12=PR1_PRU1_GPI20; 13=PR1_PRU1_GPO20; 14=GPIO4_31; 15=DRIVER OFF
0x15C8 CTRL_CORE_PAD_VOUT1_CLK reset 0x4000F
  [25] VOUT1_CLK_WAKEUPEVENT ro
    values as CTRL_CORE_PAD_VIN2A_D5.VIN2A_D5_WAKEUPEVENT
  [24] VOUT1_CLK_WAKEUPENABLE rw
    0=DISABLE (Wakeup is disabled); 1=ENABLE (Wakeup is enabled)
  [19] VOUT1_CLK_SLEWCONTROL rw
    values as CTRL_CORE_PAD_VIN2A_D5.VIN2A_D5_SLEWCONTROL
  [18] VOUT1_CLK_INPUTENABLE rw
    values as CTRL_CORE_PAD_VIN2A_D5.VIN2A_D5_INPUTENABLE
  [17] VOUT1_CLK_PULLTYPESELECT rw
    values as CTRL_CORE_PAD_VIN2A_D5.VIN2A_D5_PULLTYPESELECT
  [16] VOUT1_CLK_PULLUDENABLE rw
    values as CTRL_CORE_PAD_VIN2A_D5.VIN2A_D5_PULLUDENABLE
  [8] VOUT1_CLK_MODESELECT rw — Selects between the Default IO Timing Mode and a Virtual or Manual IO Timing Mode. Refer to the device Data Manual for definition of the required settings for a given mode of operation. When this bit is 0b1, a Virtual IO Timing Mode can be selected via the DELAYMODE field of this register, as described in, Virtual IO Timing Modes. Manual IO Timing Modes are selected via the procedure described in , Manual IO Timing Modes.
    values as CTRL_CORE_PAD_VIN2A_D5.VIN2A_D5_MODESELECT
  [7:4] VOUT1_CLK_DELAYMODE rw — This bit field selects the Virtual Timing Mode used when the MODESELECT bit is set to 0b1. See, Virtual IO Timing Modes for details.
  [3:0] VOUT1_CLK_MUXMODE rw
    0=VOUT1_CLK; 3=VIN4A_FLD0; 4=VIN3A_FLD0; 8=SPI3_CS0; 14=GPIO4_19; 15=DRIVER OFF
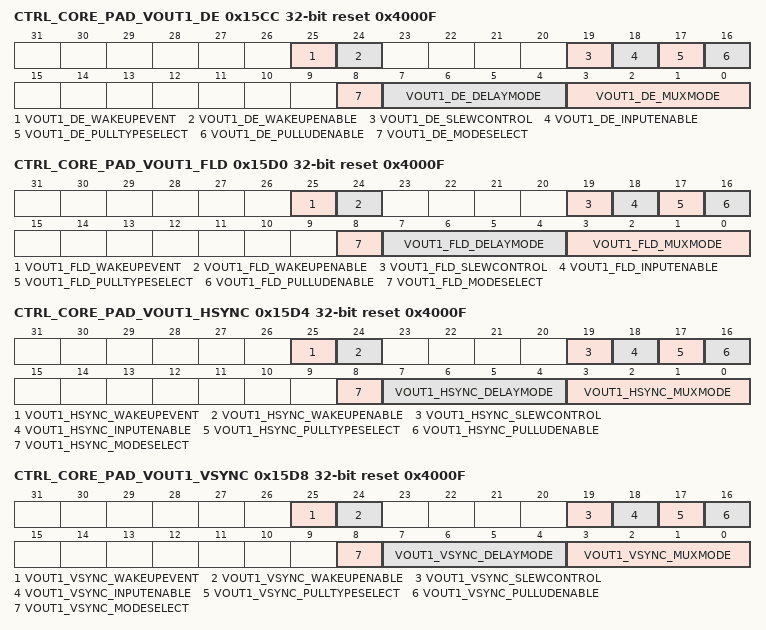
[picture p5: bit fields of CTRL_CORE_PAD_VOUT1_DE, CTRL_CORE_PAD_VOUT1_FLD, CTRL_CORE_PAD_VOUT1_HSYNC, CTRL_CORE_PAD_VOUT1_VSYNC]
0x15CC CTRL_CORE_PAD_VOUT1_DE reset 0x4000F
  [25] VOUT1_DE_WAKEUPEVENT ro
    values as CTRL_CORE_PAD_VIN2A_D5.VIN2A_D5_WAKEUPEVENT
  [24] VOUT1_DE_WAKEUPENABLE rw
    0=DISABLE (Wakeup is disabled); 1=ENABLE (Wakeup is enabled)
  [19] VOUT1_DE_SLEWCONTROL rw
    values as CTRL_CORE_PAD_VIN2A_D5.VIN2A_D5_SLEWCONTROL
  [18] VOUT1_DE_INPUTENABLE rw
    values as CTRL_CORE_PAD_VIN2A_D5.VIN2A_D5_INPUTENABLE
  [17] VOUT1_DE_PULLTYPESELECT rw
    values as CTRL_CORE_PAD_VIN2A_D5.VIN2A_D5_PULLTYPESELECT
  [16] VOUT1_DE_PULLUDENABLE rw
    values as CTRL_CORE_PAD_VIN2A_D5.VIN2A_D5_PULLUDENABLE
  [8] VOUT1_DE_MODESELECT rw — Selects between the Default IO Timing Mode and a Virtual or Manual IO Timing Mode. Refer to the device Data Manual for definition of the required settings for a given mode of operation. When this bit is 0b1, a Virtual IO Timing Mode can be selected via the DELAYMODE field of this register, as described in, Virtual IO Timing Modes. Manual IO Timing Modes are selected via the procedure described in , Manual IO Timing Modes.
    values as CTRL_CORE_PAD_VIN2A_D5.VIN2A_D5_MODESELECT
  [7:4] VOUT1_DE_DELAYMODE rw — This bit field selects the Virtual Timing Mode used when the MODESELECT bit is set to 0b1. See, Virtual IO Timing Modes for details.
  [3:0] VOUT1_DE_MUXMODE rw
    0=VOUT1_DE; 3=VIN4A_DE0; 4=VIN3A_DE0; 8=SPI3_D1; 14=GPIO4_20; 15=DRIVER OFF
0x15D0 CTRL_CORE_PAD_VOUT1_FLD reset 0x4000F
  [25] VOUT1_FLD_WAKEUPEVENT ro
    values as CTRL_CORE_PAD_VIN2A_D5.VIN2A_D5_WAKEUPEVENT
  [24] VOUT1_FLD_WAKEUPENABLE rw
    0=DISABLE (Wakeup is disabled); 1=ENABLE (Wakeup is enabled)
  [19] VOUT1_FLD_SLEWCONTROL rw
    values as CTRL_CORE_PAD_VIN2A_D5.VIN2A_D5_SLEWCONTROL
  [18] VOUT1_FLD_INPUTENABLE rw
    values as CTRL_CORE_PAD_VIN2A_D5.VIN2A_D5_INPUTENABLE
  [17] VOUT1_FLD_PULLTYPESELECT rw
    values as CTRL_CORE_PAD_VIN2A_D5.VIN2A_D5_PULLTYPESELECT
  [16] VOUT1_FLD_PULLUDENABLE rw
    values as CTRL_CORE_PAD_VIN2A_D5.VIN2A_D5_PULLUDENABLE
  [8] VOUT1_FLD_MODESELECT rw — Selects between the Default IO Timing Mode and a Virtual or Manual IO Timing Mode. Refer to the device Data Manual for definition of the required settings for a given mode of operation. When this bit is 0b1, a Virtual IO Timing Mode can be selected via the DELAYMODE field of this register, as described in, Virtual IO Timing Modes. Manual IO Timing Modes are selected via the procedure described in , Manual IO Timing Modes.
    values as CTRL_CORE_PAD_VIN2A_D5.VIN2A_D5_MODESELECT
  [7:4] VOUT1_FLD_DELAYMODE rw — This bit field selects the Virtual Timing Mode used when the MODESELECT bit is set to 0b1. See, Virtual IO Timing Modes for details.
  [3:0] VOUT1_FLD_MUXMODE rw
    0=VOUT1_FLD; 3=VIN4A_CLK0; 4=VIN3A_CLK0; 8=SPI3_CS1; 14=GPIO4_21; 15=DRIVER OFF
0x15D4 CTRL_CORE_PAD_VOUT1_HSYNC reset 0x4000F
  [25] VOUT1_HSYNC_WAKEUPEVENT ro
    values as CTRL_CORE_PAD_VIN2A_D5.VIN2A_D5_WAKEUPEVENT
  [24] VOUT1_HSYNC_WAKEUPENABLE rw
    0=DISABLE (Wakeup is disabled); 1=ENABLE (Wakeup is enabled)
  [19] VOUT1_HSYNC_SLEWCONTROL rw
    values as CTRL_CORE_PAD_VIN2A_D5.VIN2A_D5_SLEWCONTROL
  [18] VOUT1_HSYNC_INPUTENABLE rw
    values as CTRL_CORE_PAD_VIN2A_D5.VIN2A_D5_INPUTENABLE
  [17] VOUT1_HSYNC_PULLTYPESELECT rw
    values as CTRL_CORE_PAD_VIN2A_D5.VIN2A_D5_PULLTYPESELECT
  [16] VOUT1_HSYNC_PULLUDENABLE rw
    values as CTRL_CORE_PAD_VIN2A_D5.VIN2A_D5_PULLUDENABLE
  [8] VOUT1_HSYNC_MODESELECT rw — Selects between the Default IO Timing Mode and a Virtual or Manual IO Timing Mode. Refer to the device Data Manual for definition of the required settings for a given mode of operation. When this bit is 0b1, a Virtual IO Timing Mode can be selected via the DELAYMODE field of this register, as described in, Virtual IO Timing Modes. Manual IO Timing Modes are selected via the procedure described in , Manual IO Timing Modes.
    values as CTRL_CORE_PAD_VIN2A_D5.VIN2A_D5_MODESELECT
  [7:4] VOUT1_HSYNC_DELAYMODE rw — This bit field selects the Virtual Timing Mode used when the MODESELECT bit is set to 0b1. See, Virtual IO Timing Modes for details.
  [3:0] VOUT1_HSYNC_MUXMODE rw
    0=VOUT1_HSYNC; 3=VIN4A_HSYNC0; 4=VIN3A_HSYNC0; 8=SPI3_D0; 14=GPIO4_22; 15=DRIVER OFF
0x15D8 CTRL_CORE_PAD_VOUT1_VSYNC reset 0x4000F
  [25] VOUT1_VSYNC_WAKEUPEVENT ro
    values as CTRL_CORE_PAD_VIN2A_D5.VIN2A_D5_WAKEUPEVENT
  [24] VOUT1_VSYNC_WAKEUPENABLE rw
    0=DISABLE (Wakeup is disabled); 1=ENABLE (Wakeup is enabled)
  [19] VOUT1_VSYNC_SLEWCONTROL rw
    values as CTRL_CORE_PAD_VIN2A_D5.VIN2A_D5_SLEWCONTROL
  [18] VOUT1_VSYNC_INPUTENABLE rw
    values as CTRL_CORE_PAD_VIN2A_D5.VIN2A_D5_INPUTENABLE
  [17] VOUT1_VSYNC_PULLTYPESELECT rw
    values as CTRL_CORE_PAD_VIN2A_D5.VIN2A_D5_PULLTYPESELECT
  [16] VOUT1_VSYNC_PULLUDENABLE rw
    values as CTRL_CORE_PAD_VIN2A_D5.VIN2A_D5_PULLUDENABLE
  [8] VOUT1_VSYNC_MODESELECT rw — Selects between the Default IO Timing Mode and a Virtual or Manual IO Timing Mode. Refer to the device Data Manual for definition of the required settings for a given mode of operation. When this bit is 0b1, a Virtual IO Timing Mode can be selected via the DELAYMODE field of this register, as described in, Virtual IO Timing Modes. Manual IO Timing Modes are selected via the procedure described in , Manual IO Timing Modes.
    values as CTRL_CORE_PAD_VIN2A_D5.VIN2A_D5_MODESELECT
  [7:4] VOUT1_VSYNC_DELAYMODE rw — This bit field selects the Virtual Timing Mode used when the MODESELECT bit is set to 0b1. See, Virtual IO Timing Modes for details.
  [3:0] VOUT1_VSYNC_MUXMODE rw
    0=VOUT1_VSYNC; 3=VIN4A_VSYNC0; 4=VIN3A_VSYNC0; 8=SPI3_SCLK; 12=PR2_PRU1_GPI17; 13=PR2_PRU1_GPO17; 14=GPIO4_23; 15=DRIVER OFF
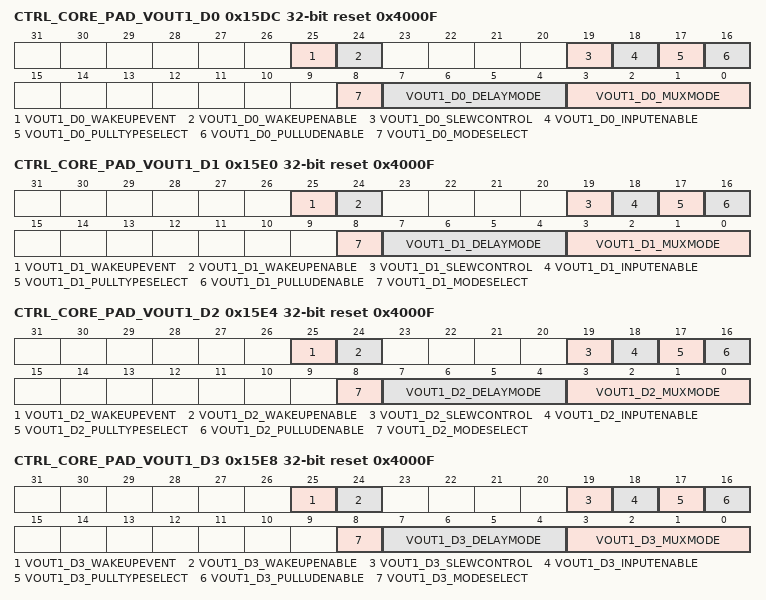
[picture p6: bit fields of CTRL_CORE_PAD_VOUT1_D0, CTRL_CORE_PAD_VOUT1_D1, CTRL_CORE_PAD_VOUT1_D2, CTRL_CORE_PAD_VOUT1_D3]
0x15DC CTRL_CORE_PAD_VOUT1_D0 reset 0x4000F
  [25] VOUT1_D0_WAKEUPEVENT ro
    values as CTRL_CORE_PAD_VIN2A_D5.VIN2A_D5_WAKEUPEVENT
  [24] VOUT1_D0_WAKEUPENABLE rw
    0=DISABLE (Wakeup is disabled); 1=ENABLE (Wakeup is enabled)
  [19] VOUT1_D0_SLEWCONTROL rw
    values as CTRL_CORE_PAD_VIN2A_D5.VIN2A_D5_SLEWCONTROL
  [18] VOUT1_D0_INPUTENABLE rw
    values as CTRL_CORE_PAD_VIN2A_D5.VIN2A_D5_INPUTENABLE
  [17] VOUT1_D0_PULLTYPESELECT rw
    values as CTRL_CORE_PAD_VIN2A_D5.VIN2A_D5_PULLTYPESELECT
  [16] VOUT1_D0_PULLUDENABLE rw
    values as CTRL_CORE_PAD_VIN2A_D5.VIN2A_D5_PULLUDENABLE
  [8] VOUT1_D0_MODESELECT rw — Selects between the Default IO Timing Mode and a Virtual or Manual IO Timing Mode. Refer to the device Data Manual for definition of the required settings for a given mode of operation. When this bit is 0b1, a Virtual IO Timing Mode can be selected via the DELAYMODE field of this register, as described in, Virtual IO Timing Modes. Manual IO Timing Modes are selected via the procedure described in , Manual IO Timing Modes.
    values as CTRL_CORE_PAD_VIN2A_D5.VIN2A_D5_MODESELECT
  [7:4] VOUT1_D0_DELAYMODE rw — This bit field selects the Virtual Timing Mode used when the MODESELECT bit is set to 0b1. See, Virtual IO Timing Modes for details.
  [3:0] VOUT1_D0_MUXMODE rw
    0=VOUT1_D0; 2=UART5_RXD; 3=VIN4A_D16; 4=VIN3A_D16; 8=SPI3_CS2; 10=PR1_UART0_CTS_N; 12=PR2_PRU1_GPI18; 13=PR2_PRU1_GPO18; 14=GPIO8_0; 15=DRIVER OFF
0x15E0 CTRL_CORE_PAD_VOUT1_D1 reset 0x4000F
  [25] VOUT1_D1_WAKEUPEVENT ro
    values as CTRL_CORE_PAD_VIN2A_D5.VIN2A_D5_WAKEUPEVENT
  [24] VOUT1_D1_WAKEUPENABLE rw
    0=DISABLE (Wakeup is disabled); 1=ENABLE (Wakeup is enabled)
  [19] VOUT1_D1_SLEWCONTROL rw
    values as CTRL_CORE_PAD_VIN2A_D5.VIN2A_D5_SLEWCONTROL
  [18] VOUT1_D1_INPUTENABLE rw
    values as CTRL_CORE_PAD_VIN2A_D5.VIN2A_D5_INPUTENABLE
  [17] VOUT1_D1_PULLTYPESELECT rw
    values as CTRL_CORE_PAD_VIN2A_D5.VIN2A_D5_PULLTYPESELECT
  [16] VOUT1_D1_PULLUDENABLE rw
    values as CTRL_CORE_PAD_VIN2A_D5.VIN2A_D5_PULLUDENABLE
  [8] VOUT1_D1_MODESELECT rw — Selects between the Default IO Timing Mode and a Virtual or Manual IO Timing Mode. Refer to the device Data Manual for definition of the required settings for a given mode of operation. When this bit is 0b1, a Virtual IO Timing Mode can be selected via the DELAYMODE field of this register, as described in, Virtual IO Timing Modes. Manual IO Timing Modes are selected via the procedure described in , Manual IO Timing Modes.
    values as CTRL_CORE_PAD_VIN2A_D5.VIN2A_D5_MODESELECT
  [7:4] VOUT1_D1_DELAYMODE rw — This bit field selects the Virtual Timing Mode used when the MODESELECT bit is set to 0b1. See, Virtual IO Timing Modes for details.
  [3:0] VOUT1_D1_MUXMODE rw
    0=VOUT1_D1; 2=UART5_TXD; 3=VIN4A_D17; 4=VIN3A_D17; 10=PR1_UART0_RTS_N; 12=PR2_PRU1_GPI19; 13=PR2_PRU1_GPO19; 14=GPIO8_1; 15=DRIVER OFF
0x15E4 CTRL_CORE_PAD_VOUT1_D2 reset 0x4000F
  [25] VOUT1_D2_WAKEUPEVENT ro
    values as CTRL_CORE_PAD_VIN2A_D5.VIN2A_D5_WAKEUPEVENT
  [24] VOUT1_D2_WAKEUPENABLE rw
    0=DISABLE (Wakeup is disabled); 1=ENABLE (Wakeup is enabled)
  [19] VOUT1_D2_SLEWCONTROL rw
    values as CTRL_CORE_PAD_VIN2A_D5.VIN2A_D5_SLEWCONTROL
  [18] VOUT1_D2_INPUTENABLE rw
    values as CTRL_CORE_PAD_VIN2A_D5.VIN2A_D5_INPUTENABLE
  [17] VOUT1_D2_PULLTYPESELECT rw
    values as CTRL_CORE_PAD_VIN2A_D5.VIN2A_D5_PULLTYPESELECT
  [16] VOUT1_D2_PULLUDENABLE rw
    values as CTRL_CORE_PAD_VIN2A_D5.VIN2A_D5_PULLUDENABLE
  [8] VOUT1_D2_MODESELECT rw — Selects between the Default IO Timing Mode and a Virtual or Manual IO Timing Mode. Refer to the device Data Manual for definition of the required settings for a given mode of operation. When this bit is 0b1, a Virtual IO Timing Mode can be selected via the DELAYMODE field of this register, as described in, Virtual IO Timing Modes. Manual IO Timing Modes are selected via the procedure described in , Manual IO Timing Modes.
    values as CTRL_CORE_PAD_VIN2A_D5.VIN2A_D5_MODESELECT
  [7:4] VOUT1_D2_DELAYMODE rw — This bit field selects the Virtual Timing Mode used when the MODESELECT bit is set to 0b1. See, Virtual IO Timing Modes for details.
  [3:0] VOUT1_D2_MUXMODE rw
    0=VOUT1_D2; 2=EMU2; 3=VIN4A_D18; 4=VIN3A_D18; 5=OBS0; 6=OBS16; 7=OBS_IRQ1; 10=PR1_UART0_RXD; 12=PR2_PRU1_GPI20; 13=PR2_PRU1_GPO20; 14=GPIO8_2; 15=DRIVER OFF
0x15E8 CTRL_CORE_PAD_VOUT1_D3 reset 0x4000F
  [25] VOUT1_D3_WAKEUPEVENT ro
    values as CTRL_CORE_PAD_VIN2A_D5.VIN2A_D5_WAKEUPEVENT
  [24] VOUT1_D3_WAKEUPENABLE rw
    0=DISABLE (Wakeup is disabled); 1=ENABLE (Wakeup is enabled)
  [19] VOUT1_D3_SLEWCONTROL rw
    values as CTRL_CORE_PAD_VIN2A_D5.VIN2A_D5_SLEWCONTROL
  [18] VOUT1_D3_INPUTENABLE rw
    values as CTRL_CORE_PAD_VIN2A_D5.VIN2A_D5_INPUTENABLE
  [17] VOUT1_D3_PULLTYPESELECT rw
    values as CTRL_CORE_PAD_VIN2A_D5.VIN2A_D5_PULLTYPESELECT
  [16] VOUT1_D3_PULLUDENABLE rw
    values as CTRL_CORE_PAD_VIN2A_D5.VIN2A_D5_PULLUDENABLE
  [8] VOUT1_D3_MODESELECT rw — Selects between the Default IO Timing Mode and a Virtual or Manual IO Timing Mode. Refer to the device Data Manual for definition of the required settings for a given mode of operation. When this bit is 0b1, a Virtual IO Timing Mode can be selected via the DELAYMODE field of this register, as described in, Virtual IO Timing Modes. Manual IO Timing Modes are selected via the procedure described in , Manual IO Timing Modes.
    values as CTRL_CORE_PAD_VIN2A_D5.VIN2A_D5_MODESELECT
  [7:4] VOUT1_D3_DELAYMODE rw — This bit field selects the Virtual Timing Mode used when the MODESELECT bit is set to 0b1. See, Virtual IO Timing Modes for details.
  [3:0] VOUT1_D3_MUXMODE rw
    0=VOUT1_D3; 2=EMU5; 3=VIN4A_D19; 4=VIN3A_D19; 5=OBS1; 6=OBS17; 7=OBS_DMARQ1; 10=PR1_UART0_TXD; 12=PR2_PRU0_GPI0; 13=PR2_PRU0_GPO0; 14=GPIO8_3; 15=DRIVER OFF
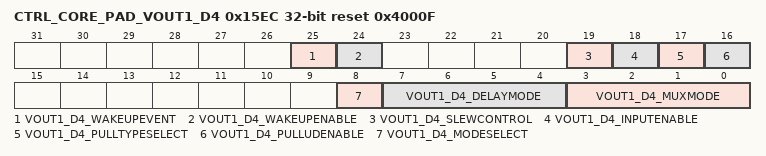
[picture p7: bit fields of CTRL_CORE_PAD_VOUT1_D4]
0x15EC CTRL_CORE_PAD_VOUT1_D4 reset 0x4000F
  [25] VOUT1_D4_WAKEUPEVENT ro
    values as CTRL_CORE_PAD_VIN2A_D5.VIN2A_D5_WAKEUPEVENT
  [24] VOUT1_D4_WAKEUPENABLE rw
    0=DISABLE (Wakeup is disabled); 1=ENABLE (Wakeup is enabled)
  [19] VOUT1_D4_SLEWCONTROL rw
    values as CTRL_CORE_PAD_VIN2A_D5.VIN2A_D5_SLEWCONTROL
  [18] VOUT1_D4_INPUTENABLE rw
    values as CTRL_CORE_PAD_VIN2A_D5.VIN2A_D5_INPUTENABLE
  [17] VOUT1_D4_PULLTYPESELECT rw
    values as CTRL_CORE_PAD_VIN2A_D5.VIN2A_D5_PULLTYPESELECT
  [16] VOUT1_D4_PULLUDENABLE rw
    values as CTRL_CORE_PAD_VIN2A_D5.VIN2A_D5_PULLUDENABLE
  [8] VOUT1_D4_MODESELECT rw — Selects between the Default IO Timing Mode and a Virtual or Manual IO Timing Mode. Refer to the device Data Manual for definition of the required settings for a given mode of operation. When this bit is 0b1, a Virtual IO Timing Mode can be selected via the DELAYMODE field of this register, as described in, Virtual IO Timing Modes. Manual IO Timing Modes are selected via the procedure described in , Manual IO Timing Modes.
    values as CTRL_CORE_PAD_VIN2A_D5.VIN2A_D5_MODESELECT
  [7:4] VOUT1_D4_DELAYMODE rw — This bit field selects the Virtual Timing Mode used when the MODESELECT bit is set to 0b1. See, Virtual IO Timing Modes for details.
  [3:0] VOUT1_D4_MUXMODE rw
    0=VOUT1_D4; 2=EMU6; 3=VIN4A_D20; 4=VIN3A_D20; 5=OBS2; 6=OBS18; 10=PR1_ECAP0_ECAP_CAPIN_APWM_O; 12=PR2_PRU0_GPI1; 13=PR2_PRU0_GPO1; 14=GPIO8_4; 15=DRIVER OFF
